# ADSP-SC83xW_HPC register map
Vendor: Analog Devices; Series: ADSP-SC83xW_HPC; File version: 3.0.3.517
CPU: 
Registers are 32-bit, read-write, reset 0x0 unless marked. A register's access mark holds for its fields unless they carry their own. Offsets are from the block's base; [hi:lo] are bit positions; {n}, {i} and the like mark numbered series.

## CRC0 — Cyclic Redundancy Check Unit
Base 0x310A5000
Same registers: CRC1 0x310A6000, CRC2 0x310AA000, CRC3 0x310AB000
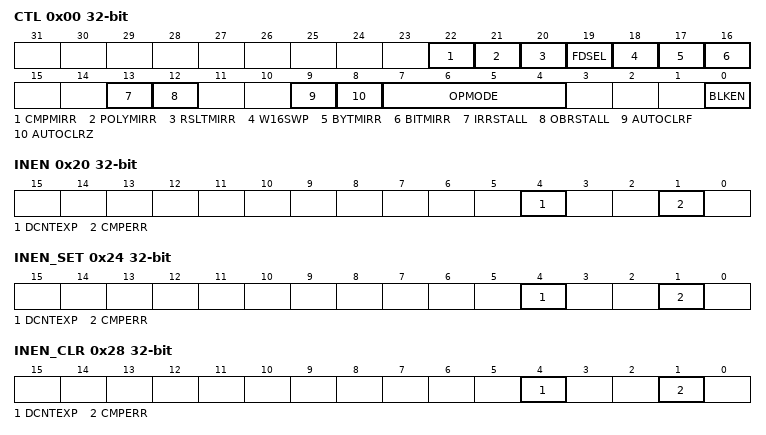
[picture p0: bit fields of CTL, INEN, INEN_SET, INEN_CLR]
0x00 CTL — Control Register
  [22] CMPMIRR — COMPARE Register Mirroring
  [21] POLYMIRR — Polynomial Register Mirroring
  [20] RSLTMIRR — Result Register Mirroring
  [19] FDSEL — FIFO Data Select
  [18] W16SWP — Word16 Swapping
  [17] BYTMIRR — Byte Mirroring
  [16] BITMIRR — Bit Mirroring
  [13] IRRSTALL — Intermediate Result Ready Stall
  [12] OBRSTALL — Output Buffer Ready Stall
  [9] AUTOCLRF — Auto Clear to One
  [8] AUTOCLRZ — Auto Clear to Zero
  [7:4] OPMODE — Operation Mode
  [0] BLKEN — Block Enable
0x04 DCNT — Data Word Count Register
  [31:0] VALUE range 0x00000000..0xFFFFFFFF — Data Word Count
0x08 DCNTRLD — Data Word Count Reload Register
  [31:0] VALUE range 0x00000000..0xFFFFFFFF — Reload Value
0x14 COMP — Data Compare Register
  [31:0] VALUE range 0x00000000..0xFFFFFFFF — Expected CRC Result Value
0x18 FILLVAL — Fill Value Register
  [31:0] VALUE range 0x00000000..0xFFFFFFFF — Memory Fill Value
0x1C DFIFO — Data FIFO Register
  [31:0] VALUE range 0x00000000..0xFFFFFFFF — Data FIFO Value
0x20 INEN — Interrupt Enable Register
  [4] DCNTEXP — Data Count Expired (Status) Interrupt Enable
    0=DCNTEXP_MSK (Disable (mask) interrupt); 1=DCNTEXP_UMSK (Enable (unmask) interrupt)
  [1] CMPERR — Compare Error Interrupt Enable
    0=CMPERR_MSK (Disable (mask) interrupt); 1=CMPERR_UMSK (Enable (unmask) interrupt)
0x24 INEN_SET — Interrupt Enable Set Register
  [4] DCNTEXP — Data Count Expired (Status) Interrupt Enable Set
  [1] CMPERR — Compare Error Interrupt
0x28 INEN_CLR — Interrupt Enable Clear Register
  [4] DCNTEXP — Data Count Expired
  [1] CMPERR — Compare Error Clear
0x2C POLY — Polynomial Register
  [31:0] VALUE range 0x00000000..0xFFFFFFFF — CRC Polynomial Value
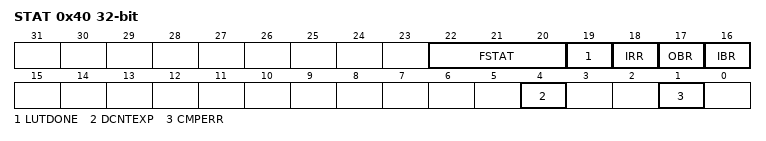
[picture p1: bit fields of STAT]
0x40 STAT — Status Register
  [22:20] FSTAT ro — FIFO Status
  [19] LUTDONE ro — Look-Up Table Done
  [18] IRR ro — Intermediate Result Ready
  [17] OBR ro — Output Buffer Ready
  [16] IBR ro — Input Buffer Ready
  [4] DCNTEXP — Data Count Expired
  [1] CMPERR — Compare Error
0x44 DCNTCAP — Data Count Capture Register
  [31:0] VALUE range 0x00000000..0xFFFFFFFF — Data Count Capture Value
0x4C RESULT_FIN — CRC Final Result Register
  [31:0] VALUE range 0x00000000..0xFFFFFFFF — Computed CRC
0x50 RESULT_CUR — CRC Current Result Register
  [31:0] VALUE range 0x00000000..0xFFFFFFFF — Intermediate CRC Result

## CSTSGENWR0
Base 0x3110E000
Same registers: TSGENWR0 0x310AE000
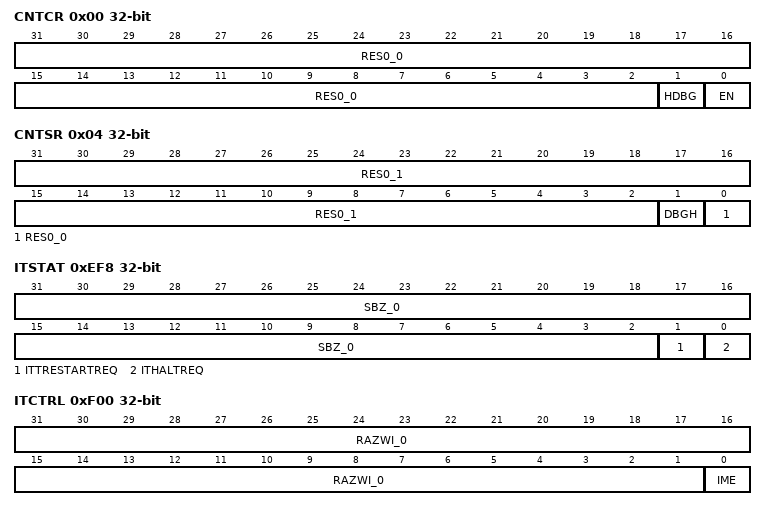
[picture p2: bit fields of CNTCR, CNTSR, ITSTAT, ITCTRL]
0x00 CNTCR — Counter Control Register
  [31:2] RES0_0 range 0x00000000..0x3FFFFFFF, [1] HDBG, [0] EN
0x04 CNTSR — Counter Status Register
  [31:2] RES0_1 ro, [1] DBGH ro, [0] RES0_0 ro
0x08 CNTCVL — Current value of Counter[31:0]
  [31:0] CNTCVL32 range 0x00000000..0xFFFFFFFF
0x0C CNTCVU — Current value of Counter[63:32]
  [31:0] CNTCVU32 range 0x00000000..0xFFFFFFFF
0x20 CNTFID0 — Base Frequency ID register
  [31:0] Freq range 0x00000000..0xFFFFFFFF
0xEF8 ITSTAT — Integration Test Status Register
  [31:2] SBZ_0 ro, [1] ITTRESTARTREQ ro, [0] ITHALTREQ ro
0xF00 ITCTRL — Integration Mode Control Register
  [31:1] RAZWI_0 range 0x00000000..0x7FFFFFFF, [0] IME range 0x00000000..0x00000001
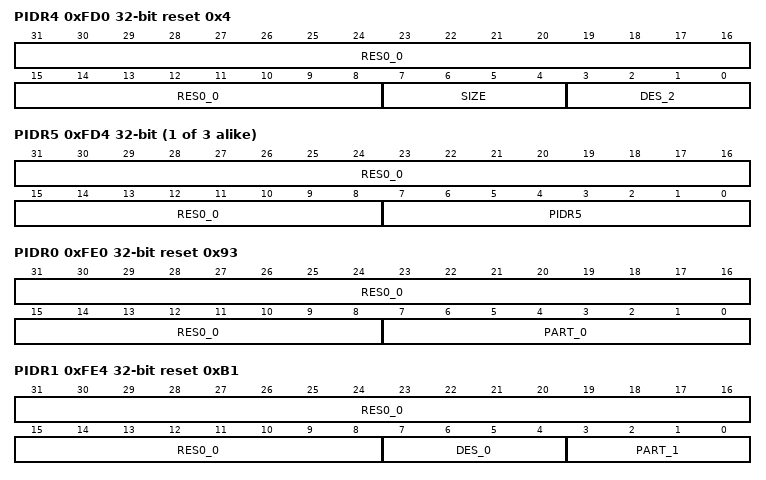
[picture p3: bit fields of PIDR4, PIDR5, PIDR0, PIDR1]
0xFD0 PIDR4 reset 0x4 — Peripheral Identification Register 4
  [31:8] RES0_0 ro, [7:4] SIZE ro, [3:0] DES_2 ro
{0xFC0+4i} PIDR{i} (i=5..7) — Peripheral Identification Register {i}
  [31:8] RES0_0 ro, [7:0] PIDR{i} ro
0xFE0 PIDR0 reset 0x93 — Peripheral Identification Register 0
  [31:8] RES0_0 ro, [7:0] PART_0 ro
0xFE4 PIDR1 reset 0xB1 — Peripheral Identification Register 1
  [31:8] RES0_0 ro, [7:4] DES_0 ro, [3:0] PART_1 ro
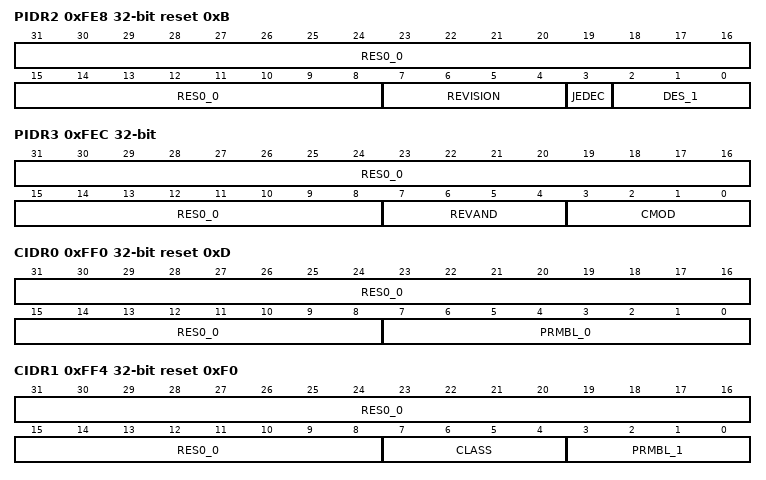
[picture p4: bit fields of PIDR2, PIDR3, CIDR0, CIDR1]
0xFE8 PIDR2 reset 0xB — Peripheral Identification Register 2
  [31:8] RES0_0 ro, [7:4] REVISION ro, [3] JEDEC ro, [2:0] DES_1 ro
0xFEC PIDR3 — Peripheral Identification Register 3
  [31:8] RES0_0 ro, [7:4] REVAND ro, [3:0] CMOD ro
0xFF0 CIDR0 reset 0xD — Component Identification Register 0
  [31:8] RES0_0 ro, [7:0] PRMBL_0 ro
0xFF4 CIDR1 reset 0xF0 — Component Identification Register 1
  [31:8] RES0_0 ro, [7:4] CLASS ro, [3:0] PRMBL_1 ro
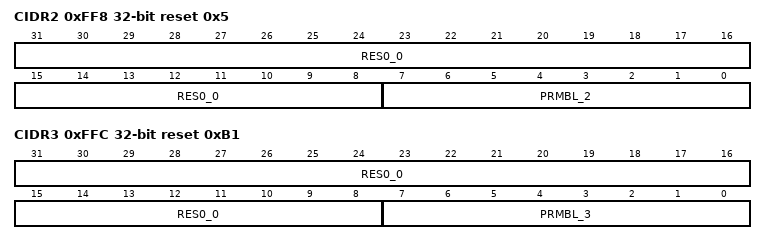
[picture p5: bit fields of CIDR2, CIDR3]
0xFF8 CIDR2 reset 0x5 — Component Identification Register 2
  [31:8] RES0_0 ro, [7:0] PRMBL_2 ro
0xFFC CIDR3 reset 0xB1 — Component Identification Register 3
  [31:8] RES0_0 ro, [7:0] PRMBL_3 ro

## TSGENRD0
Base 0x310AF000
Registers as CSTSGENWR0, without CNTCR, CNTSR, CNTCVL, CNTCVU, CNTFID0, ITSTAT, ITCTRL; these are added or differ:
0x00 CNTCVLREAD — Current value of Counter[31:0]
  [31:0] CNTCVL32 ro
0x04 CNTCVUREAD — Current value of Counter[63:32]
  [31:0] CNTCVU32 ro
